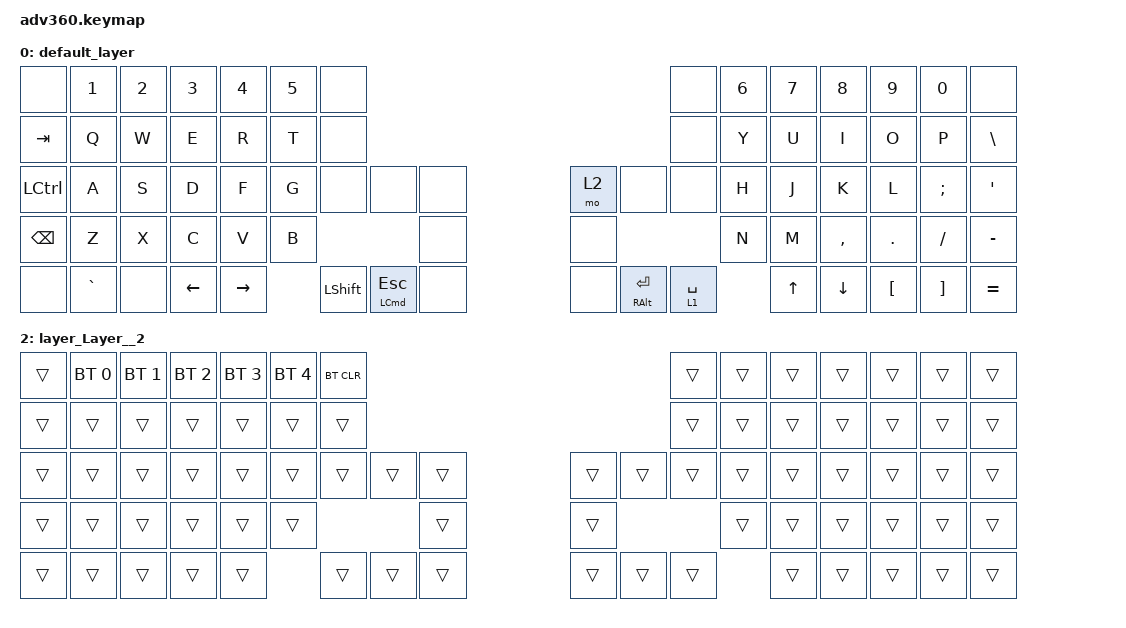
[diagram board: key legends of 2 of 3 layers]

/*
 * Copyright (c) 2020 The ZMK Contributors
 *
 * SPDX-License-Identifier: MIT
 */


/* THIS FILE WAS GENERATED!
 *
 * This file was generated automatically. You may or may not want to
 * edit it directly.
 */

#include <behaviors.dtsi>
#include <dt-bindings/zmk/keys.h>
#include <dt-bindings/zmk/bt.h>

/ {
  behaviors {
    #include "macros.dtsi"
    #include "version.dtsi"

    hm: homerow_mods {
        compatible = "zmk,behavior-hold-tap";
        label = "HOMEROW_MODS";
        #binding-cells = <2>;
        tapping-term-ms = <200>;
        quick_tap_ms = <175>;
        flavor = "tap-preferred";
        bindings = <&kp>, <&kp>;
    };
  };

    keymap {
        compatible = "zmk,keymap";


        default_layer {
            bindings = <
         &none     &kp N1  &kp N2    &kp N3     &kp N4  &kp N5                     &none                                                                               &none  &kp N6  &kp N7     &kp N8    &kp N9    &kp N0      &none
       &kp TAB      &kp Q   &kp W     &kp E      &kp R   &kp T                     &none                                                                               &none   &kp Y   &kp U      &kp I     &kp O     &kp P   &kp BSLH
     &kp LCTRL      &kp A   &kp S     &kp D      &kp F   &kp G                     &none                 &none   &none                   &mo 2            &none        &none   &kp H   &kp J      &kp K     &kp L  &kp SEMI    &kp SQT
 &kp BACKSPACE      &kp Z   &kp X     &kp C      &kp V   &kp B                                                   &none                   &none                                 &kp N   &kp M  &kp COMMA   &kp DOT  &kp FSLH  &kp MINUS
         &none  &kp GRAVE   &none  &kp LEFT  &kp RIGHT                    &kp LEFT_SHIFT  &mt LEFT_COMMAND ESC   &none                   &none  &mt RALT RETURN  &lt 1 SPACE          &kp UP   &kp DOWN  &kp LBKT  &kp RBKT  &kp EQUAL
            >;
        };

        layer_Layer__1 {
            bindings = <
 &kp PLUS         &none         &none         &none         &none         &none            &trans                                                  &trans         &none          &none           &none                 &none                  &none     &kp UNDERSCORE
   &trans        &trans        &trans        &trans        &trans        &trans            &trans                                                  &trans        &trans         &trans          &trans                &trans                 &trans           &kp PIPE
   &trans  &kp NUMBER_1  &kp NUMBER_2  &kp NUMBER_3  &kp NUMBER_4  &kp NUMBER_5            &trans  &trans  &trans                  &trans  &trans  &trans  &kp NUMBER_6   &kp NUMBER_7    &kp NUMBER_8          &kp NUMBER_9           &kp NUMBER_0  &kp DOUBLE_QUOTES
   &trans      &kp EXCL   &kp AT_SIGN     &kp POUND    &kp DOLLAR   &kp PERCENT                            &trans                  &trans                     &kp CARET  &kp AMPERSAND        &kp STAR  &kp LEFT_PARENTHESIS  &kp RIGHT_PARENTHESIS     &kp UNDERSCORE
   &trans        &trans        &trans        &trans        &trans                          &trans  &trans  &trans                  &trans  &trans  &trans                       &trans  &kp LEFT_BRACE       &kp RIGHT_BRACE               &kp PLUS
            >;
        };

        layer_Layer__2 {
            bindings = <
 &trans  &bt BT_SEL 0  &bt BT_SEL 1  &bt BT_SEL 2  &bt BT_SEL 3  &bt BT_SEL 4            &bt BT_CLR                                                  &trans  &trans  &trans  &trans  &trans  &trans  &trans
 &trans        &trans        &trans        &trans        &trans        &trans                &trans                                                  &trans  &trans  &trans  &trans  &trans  &trans  &trans
 &trans        &trans        &trans        &trans        &trans        &trans                &trans  &trans  &trans                  &trans  &trans  &trans  &trans  &trans  &trans  &trans  &trans  &trans
 &trans        &trans        &trans        &trans        &trans        &trans                                &trans                  &trans                  &trans  &trans  &trans  &trans  &trans  &trans
 &trans        &trans        &trans        &trans        &trans                              &trans  &trans  &trans                  &trans  &trans  &trans          &trans  &trans  &trans  &trans  &trans
            >;
        };

    };
};
